# VPE_CHR_US_INST_0 register map
Vendor: Texas Instruments
Peripheral module from a debugger description file (folder DRA75x_DRA74x).
Registers are 32-bit, read-write, reset 0x0 unless marked. A register's access mark holds for its fields unless they carry their own. Offsets are as the file gives them; lines under a group give offsets from that group; [hi:lo] are bit positions; {n}, {i} and the like mark numbered series; 'fields as' and 'values as' point back to an identical list; <NAME> marks a mode.

## VPE_CHR_US_INST_0
0x00 VPE_PID ro
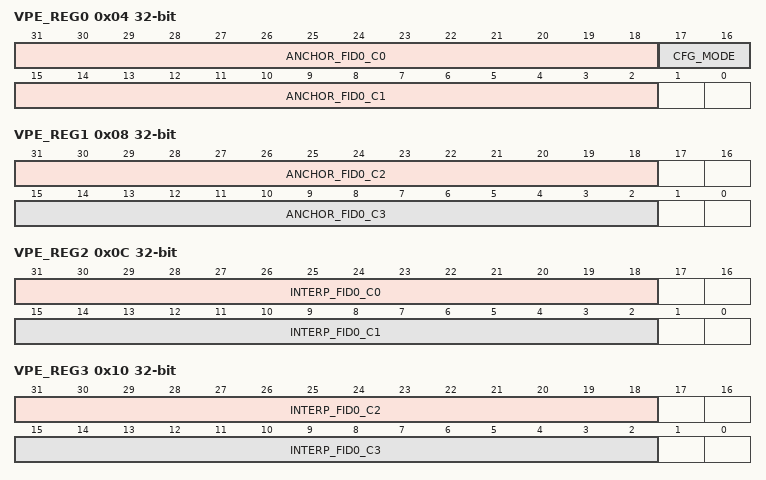
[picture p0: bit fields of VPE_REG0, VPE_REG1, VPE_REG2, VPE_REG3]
0x04 VPE_REG0
  [31:18] ANCHOR_FID0_C0 — C0 coefficient for Anchor Pixel. Use when field_id = 0
  [17:16] CFG_MODE — 0x0 : Mode A
    1=Mode_B
  [15:2] ANCHOR_FID0_C1 — C1 coefficient for Anchor Pixel. Use when field_id = 0
0x08 VPE_REG1
  [31:18] ANCHOR_FID0_C2 — C2 coefficient for Anchor Pixel. Use when field_id = 0
  [15:2] ANCHOR_FID0_C3 — C3 coefficient for Anchor Pixel. Use when field_id = 0
0x0C VPE_REG2
  [31:18] INTERP_FID0_C0 — C0 coefficient for Interpolated Pixel. Use when field_id = 0
  [15:2] INTERP_FID0_C1 — C1 coefficient for Interpolated Pixel. Use when field_id = 0
0x10 VPE_REG3
  [31:18] INTERP_FID0_C2 — C2 coefficient for Interpolated Pixel. Use when field_id = 0
  [15:2] INTERP_FID0_C3 — C3 coefficient for Interpolated Pixel. Use when field_id = 0
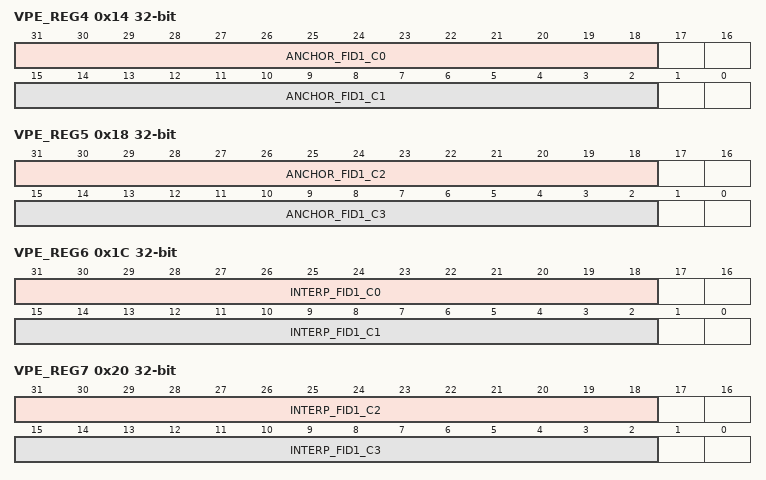
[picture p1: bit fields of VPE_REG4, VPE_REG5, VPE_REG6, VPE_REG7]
0x14 VPE_REG4 access per field
  [31:18] ANCHOR_FID1_C0 rw — C0 coefficient for Anchor Pixel. Use when field_id = 1
  [15:2] ANCHOR_FID1_C1 rw — C1 coefficient for Anchor Pixel. Use when field_id = 1
0x18 VPE_REG5 access per field
  [31:18] ANCHOR_FID1_C2 rw — C2 coefficient for Anchor Pixel. Use when field_id = 1
  [15:2] ANCHOR_FID1_C3 rw — C3 coefficient for Anchor Pixel. Use when field_id = 1
0x1C VPE_REG6 access per field
  [31:18] INTERP_FID1_C0 rw — C0 coefficient for Interpolated Pixel. Use when field_id = 1
  [15:2] INTERP_FID1_C1 rw — C1 coefficient for Interpolated Pixel. Use when field_id = 1
0x20 VPE_REG7 access per field
  [31:18] INTERP_FID1_C2 rw — C2 coefficient for Interpolated Pixel. Use when field_id = 1
  [15:2] INTERP_FID1_C3 rw — C3 coefficient for Interpolated Pixel. Use when field_id = 1
